AUTOSAR XML (schema 19-11)
standard types defined: UInt16, UInt8
package /ComponentTypes
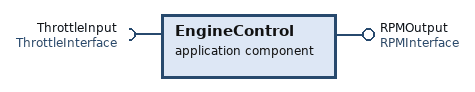
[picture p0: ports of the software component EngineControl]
  application sw component type EngineControl: category=APPLICATION_LAYER
    provide port RPMOutput: provided-interface=RPMInterface
    require port ThrottleInput: required-interface=ThrottleInterface
    behavior EngineControlBehavior
package /Interfaces
  sender receiver interface RPMInterface
    data RPMValue: type=UInt16
  sender receiver interface ThrottleInterface
    data ThrottleValue: type=UInt8
